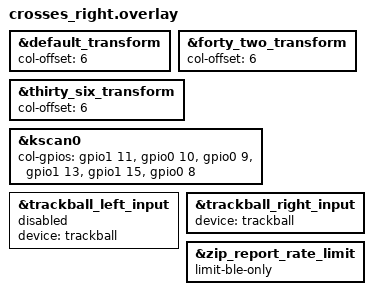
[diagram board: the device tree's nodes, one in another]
/*
 * Copyright (c) 2025 Vincent Franco
 * SPDX-License-Identifier: MIT
 */
#include "crosses.dtsi"
#include "pmw3360.dtsi"
#include "split_input.dtsi"

#include <zephyr/dt-bindings/input/input-event-codes.h>
#include <dt-bindings/zmk/input_transform.h>


&default_transform {
  col-offset = <6>;
};

&forty_two_transform {
  col-offset = <6>;
};

&thirty_six_transform {
  col-offset = <6>;
};


&kscan0 {
  col-gpios
    = <&gpio1 11 (GPIO_ACTIVE_HIGH | GPIO_PULL_DOWN)>
    , <&gpio0 10  (GPIO_ACTIVE_HIGH | GPIO_PULL_DOWN)>
    , <&gpio0 9 (GPIO_ACTIVE_HIGH | GPIO_PULL_DOWN)>
    , <&gpio1 13 (GPIO_ACTIVE_HIGH | GPIO_PULL_DOWN)>
    , <&gpio1 15 (GPIO_ACTIVE_HIGH | GPIO_PULL_DOWN)>
    , <&gpio0 8 (GPIO_ACTIVE_HIGH | GPIO_PULL_DOWN)>
    ;

};

&trackball_left_input { 
	device = <&trackball>;
  status = "disabled";
};

&trackball_right_input { 
	device = <&trackball>;
	status = "okay";
};


&zip_report_rate_limit {
    limit-ble-only;
};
